# MSP432P411V register map
Vendor: Texas Instruments; File version: 3.230
CPU: 
Registers are 32-bit, read-write, reset 0x0 unless marked. A register's access mark holds for its fields unless they carry their own. Offsets are from the block's base; [hi:lo] are bit positions; {n}, {i} and the like mark numbered series; 'fields as' and 'values as' point back to an identical list.

## SYSCTL_A
Base 0xE0043000
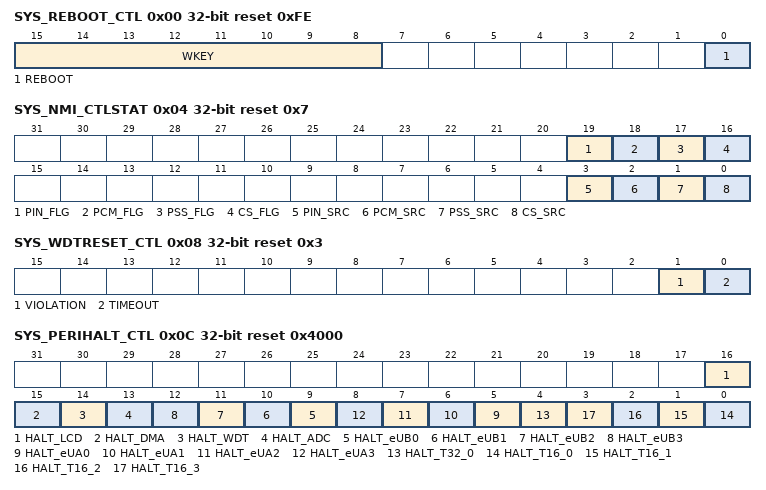
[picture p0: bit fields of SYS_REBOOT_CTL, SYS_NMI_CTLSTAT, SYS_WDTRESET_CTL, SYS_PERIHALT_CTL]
0x00 SYS_REBOOT_CTL reset 0xFE — Reboot Control Register
  [15:8] WKEY wo — Key to enable writes to bit 0
  [0] REBOOT wo — Write 1 initiates a Reboot of the device
0x04 SYS_NMI_CTLSTAT reset 0x7 — NMI Control and Status Register
  [19] PIN_FLG — RSTn/NMI pin was the source of NMI
    0=Indicates the RSTn_NMI pin was not the source of NMI; 1=Indicates the RSTn_NMI pin was the source of NMI
  [18] PCM_FLG ro — PCM interrupt was the source of NMI
    0=indicates the PCM interrupt was not the source of NMI; 1=indicates the PCM interrupt was the source of NMI
  [17] PSS_FLG ro — PSS interrupt was the source of NMI
    0=indicates the PSS interrupt was not the source of NMI; 1=indicates the PSS interrupt was the source of NMI
  [16] CS_FLG ro — CS interrupt was the source of NMI
    0=indicates CS interrupt was not the source of NMI; 1=indicates CS interrupt was the source of NMI
  [3] PIN_SRC — RSTn/NMI pin configuration Note: When the device enters LPM3/LPM4 modes of operation, the functionality selected by this bit is retained. If selected as an NMI, activity on this pin in LPM3/LPM4 wakes the device and processes the interrupt, without causing a POR. If selected as a Reset, activity on this pin in LPM3/LPM4 causes a device-level POR When the device enters LPM3.5/LPM4.5 modes of operation, this bit is always cleared to 0. In other words, the RSTn/NMI pin always assumes a reset functionality in LPM3.5/LPM4.5 modes.
    0=Configures the RSTn_NMI pin as a source of POR Class Reset; 1=Configures the RSTn_NMI pin as a source of NMI
  [2] PCM_SRC — PCM interrupt as a source of NMI
    0=Disbles the PCM interrupt as a source of NMI; 1=Enables the PCM interrupt as a source of NMI
  [1] PSS_SRC — PSS interrupt as a source of NMI
    0=Disables the PSS interrupt as a source of NMI; 1=Enables the PSS interrupt as a source of NMI
  [0] CS_SRC — CS interrupt as a source of NMI
    0=Disables CS interrupt as a source of NMI; 1=Enables CS interrupt as a source of NMI
0x08 SYS_WDTRESET_CTL reset 0x3 — Watchdog Reset Control Register
  [1] VIOLATION — WDT password violation reset type
    0=WDT password violation event generates Soft reset; 1=WDT password violation event generates Hard reset
  [0] TIMEOUT — WDT timeout reset type
    0=WDT timeout event generates Soft reset; 1=WDT timeout event generates Hard reset
0x0C SYS_PERIHALT_CTL reset 0x4000 — Peripheral Halt Control Register
  [all] fields
    0=IP operation unaffected when CPU is halted; 1=freezes IP operation when CPU is halted
  [16] HALT_LCD — Freezes IP operation when CPU is halted
  [15] HALT_DMA — Freezes IP operation when CPU is halted
  [14] HALT_WDT — Freezes IP operation when CPU is halted
  [13] HALT_ADC — Freezes IP operation when CPU is halted
  [n+9] HALT_eUB{n} (n=0..3) — Freezes IP operation when CPU is halted
  [n+5] HALT_eUA{n} (n=0..3) — Freezes IP operation when CPU is halted
  [4] HALT_T32_0 — Freezes IP operation when CPU is halted
  [n] HALT_T16_{n} (n=0..3) — Freezes IP operation when CPU is halted
0x10 SYS_SRAM_SIZE ro reset not defined — SRAM Size Register
  [31:0] SIZE — Indicates the size of SRAM on the device
0x14 SYS_SRAM_NUMBANKS ro reset not defined — SRAM Number of Banks Register
  [31:0] NUM — Indicates the number of SRAM banks on the device.
0x18 SYS_SRAM_NUMBLOCKS ro reset not defined — SRAM Number of Blocks Register
  [31:0] NUM — Indicates the number of SRAM blocks on the device.
0x20 SYS_MAINFLASH_SIZE ro reset not defined — Flash Main Memory Size Register
  [31:0] SIZE — Flash main memory size
0x24 SYS_INFOFLASH_SIZE ro reset not defined — Flash Information Memory Size Register
  [31:0] SIZE — Flash information memory size
0x30 SYS_DIO_GLTFLT_CTL reset 0x1 — Digital I/O Glitch Filter Control Register
  [0] GLTCH_EN — Glitch filter enable
    0=Disables glitch filter on the digital I/Os; 1=Enables glitch filter on the digital I/Os
0x40 SYS_SECDATA_UNLOCK — IP Protected Secure Zone Data Access Unlock Register
  [15:0] UNLKEY — Unlock key
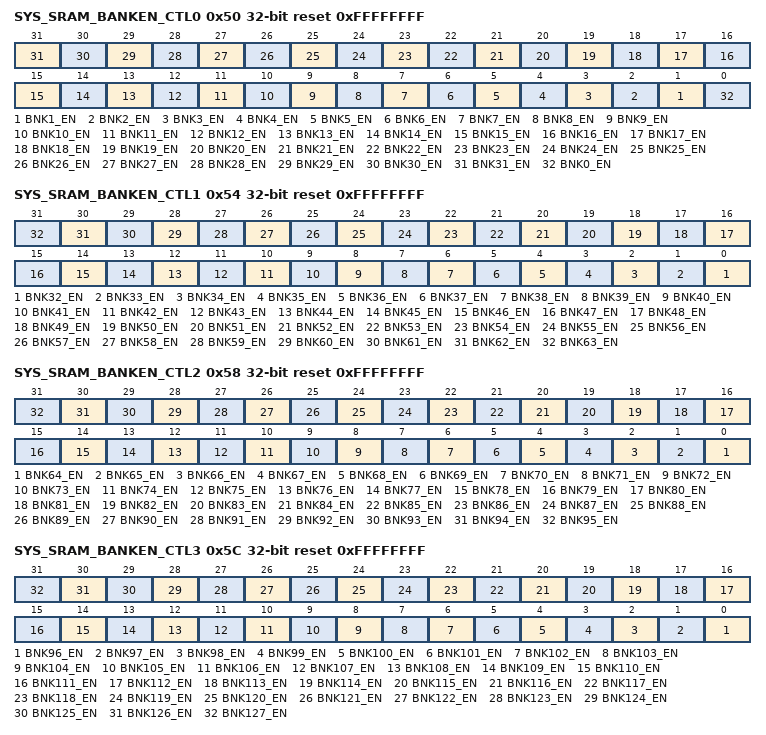
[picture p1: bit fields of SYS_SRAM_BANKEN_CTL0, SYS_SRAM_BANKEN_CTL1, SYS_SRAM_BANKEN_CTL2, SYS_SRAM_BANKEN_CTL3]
0x50 SYS_SRAM_BANKEN_CTL0 reset 0xFFFFFFFF — SRAM Bank Enable Control Register 0
  [n] BNK{n}_EN (n=1..31) — When 1, enables Bank{n} of the SRAM
    0=Disables Bank{n} of the SRAM; 1=Enables Bank{n} of the SRAM
  [0] BNK0_EN ro — When 1, enables Bank0 of the SRAM
0x54 SYS_SRAM_BANKEN_CTL1 reset 0xFFFFFFFF — SRAM Bank Enable Control Register 1
  [n-32] BNK{n}_EN (n=32..63) — When 1, enables Bank{n} of the SRAM
    values as SYS_SRAM_BANKEN_CTL0.BNK1_EN
0x58 SYS_SRAM_BANKEN_CTL2 reset 0xFFFFFFFF — SRAM Bank Enable Control Register 2
  [n-64] BNK{n}_EN (n=64..95) — When 1, enables Bank{n} of the SRAM
    values as SYS_SRAM_BANKEN_CTL0.BNK1_EN
0x5C SYS_SRAM_BANKEN_CTL3 reset 0xFFFFFFFF — SRAM Bank Enable Control Register 3
  [n-96] BNK{n}_EN (n=96..127) — When 1, enables Bank{n} of the SRAM
    values as SYS_SRAM_BANKEN_CTL0.BNK1_EN
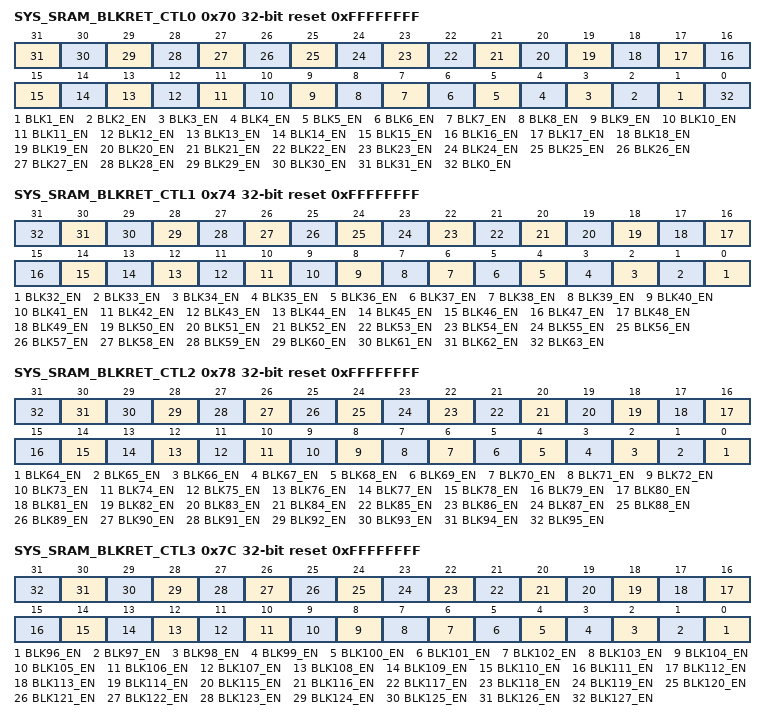
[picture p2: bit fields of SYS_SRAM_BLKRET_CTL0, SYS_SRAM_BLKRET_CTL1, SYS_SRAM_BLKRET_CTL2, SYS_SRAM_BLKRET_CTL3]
0x70 SYS_SRAM_BLKRET_CTL0 reset 0xFFFFFFFF — SRAM Block Retention Control Register 0
  [n] BLK{n}_EN (n=1..31) — When 1, Block{n} of the SRAM is retained in LPM3 and LPM4
    0=Block{n} of the SRAM is not retained in LPM3 or LPM4; 1=Block{n} of the SRAM is retained in LPM3 and LPM4
  [0] BLK0_EN ro — Block0 is always retained in LPM3, LPM4 and LPM3.5 modes of operation
0x74 SYS_SRAM_BLKRET_CTL1 reset 0xFFFFFFFF — SRAM Block Retention Control Register 1
  [n-32] BLK{n}_EN (n=32..63) — When 1, Block{n} of the SRAM is retained in LPM3 and LPM4
    values as SYS_SRAM_BLKRET_CTL0.BLK1_EN
0x78 SYS_SRAM_BLKRET_CTL2 reset 0xFFFFFFFF — SRAM Block Retention Control Register 2
  [n-64] BLK{n}_EN (n=64..95) — When 1, Block{n} of the SRAM is retained in LPM3 and LPM4
    values as SYS_SRAM_BLKRET_CTL0.BLK1_EN
0x7C SYS_SRAM_BLKRET_CTL3 reset 0xFFFFFFFF — SRAM Block Retention Control Register 3
  [n-96] BLK{n}_EN (n=96..127) — When 1, Block{n} of the SRAM is retained in LPM3 and LPM4
    values as SYS_SRAM_BLKRET_CTL0.BLK1_EN
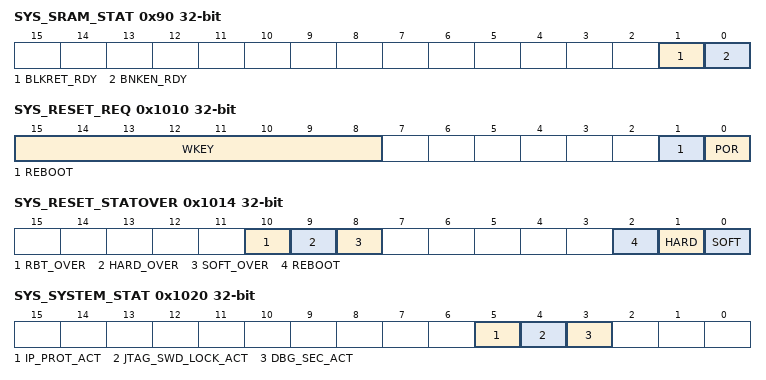
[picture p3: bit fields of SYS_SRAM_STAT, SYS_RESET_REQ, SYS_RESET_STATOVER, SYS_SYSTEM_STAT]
0x90 SYS_SRAM_STAT ro reset not defined — SRAM Status Register
  [1] BLKRET_RDY — When 1, indicates SRAM is ready for access and blocks can be enabled/disabled for retention.
    0=SRAM blocks are being set up for retention. Entry into LPM3, LPM4 should not be attempted until this bit is set to 1; 1=SRAM is ready for accesses. All SRAM blocks are enabled/disabled for retention according to values of registers SYS_SRAM_BLKRET_CTLx (x = 0,1,2,3)
  [0] BNKEN_RDY — When 1, indicates SRAM is ready for access and banks can be enabled/disabled.
    0=SRAM is not ready for accesses. Banks are undergoing an enable or disable sequence, and reads or writes to SRAM are stalled until the banks are ready.; 1=SRAM is ready for accesses. All SRAM banks are enabled/disabled according to values of registers SYS_SRAM_BANKEN_CTLx (x=0,1,2,3)
0x1000 SYS_MASTER_UNLOCK — Master Unlock Register
  [15:0] UNLKEY — Unlock Key
0x1004 SYS_BOOTOVER_REQ[0] — Boot Override Request Register
  [31:0] REGVAL — Value set by debugger, read and clear by the CPU
0x1008 SYS_BOOTOVER_REQ[1] — Boot Override Request Register
  [31:0] REGVAL — Value set by debugger, read and clear by the CPU
0x100C SYS_BOOTOVER_ACK — Boot Override Acknowledge Register
  [31:0] REGVAL — Value set by CPU, read/clear by the debugger
0x1010 SYS_RESET_REQ reset not defined — Reset Request Register
  [15:8] WKEY wo — Write key
  [1] REBOOT wo — Generate Reboot_Reset
  [0] POR wo — Generate POR
0x1014 SYS_RESET_STATOVER (reset mask 0x700) — Reset Status and Override Register
  [10] RBT_OVER — Reboot Reset overwrite request
  [9] HARD_OVER — HARD_Reset overwrite request
  [8] SOFT_OVER — SOFT_Reset overwrite request
  [2] REBOOT ro — Indicates if Reboot Reset is active
  [1] HARD ro — Indicates if HARD Reset is active
  [0] SOFT ro — Indicates if SOFT Reset is active
0x1020 SYS_SYSTEM_STAT ro reset not defined — System Status Register
  [5] IP_PROT_ACT — Indicates if IP protection is active
  [4] JTAG_SWD_LOCK_ACT — Indicates if JTAG and SWD Lock is active
  [3] DBG_SEC_ACT — Debug Security active
